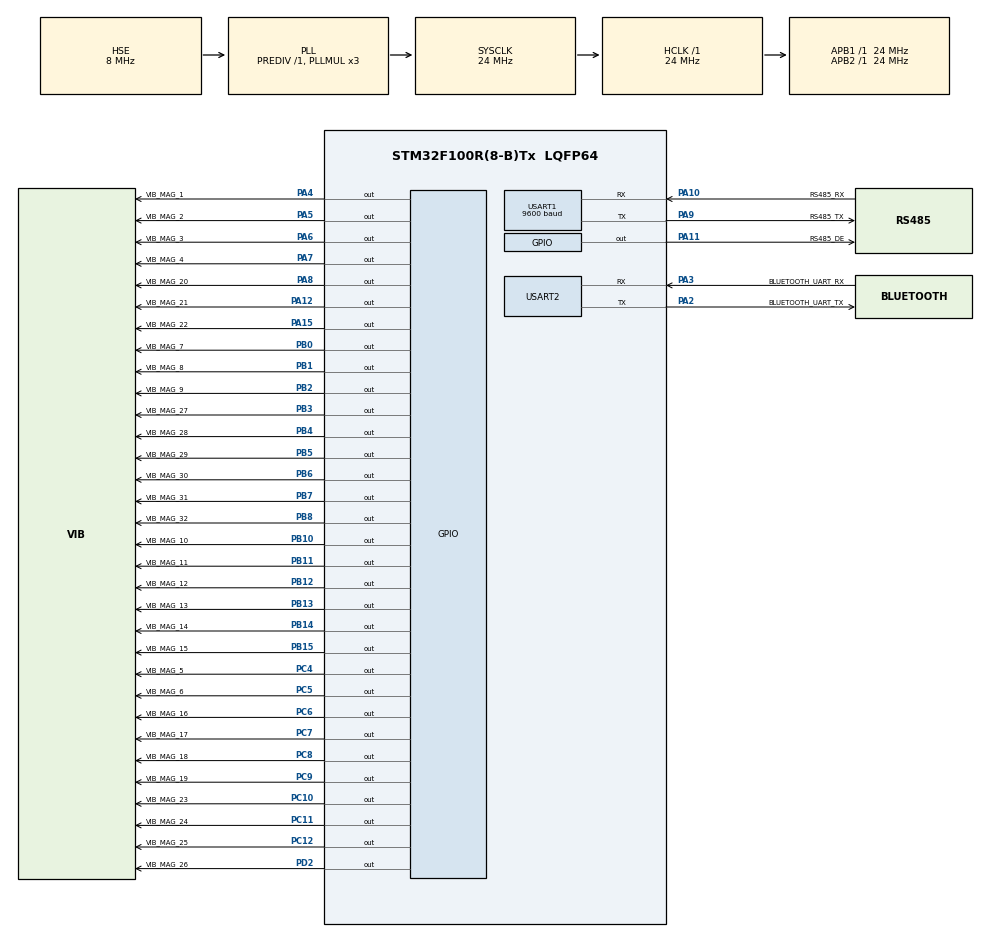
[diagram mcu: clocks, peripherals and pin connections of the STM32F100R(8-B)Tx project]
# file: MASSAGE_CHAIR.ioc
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FREERTOS.Tasks01=defaultTask,-3,128,StartDefaultTask,As weak,NULL,Dynamic,NULL,NULL
Mcu.Family=STM32F1
Mcu.Name=STM32F100R(8-B)Tx
Mcu.Package=LQFP64
NVIC.PriorityGroup=NVIC_PRIORITYGROUP_4
PA10.GPIO_Label=RS485_RX
PA10.Mode=Asynchronous
PA10.Signal=USART1_RX
PA11.GPIO_Label=RS485_DE
PA11.Signal=GPIO_Output
PA12.GPIO_Label=VIB_MAG_21
PA12.Signal=GPIO_Output
PA13.Mode=Serial_Wire
PA13.Signal=SYS_JTMS-SWDIO
PA14.Mode=Serial_Wire
PA14.Signal=SYS_JTCK-SWCLK
PA15.GPIO_Label=VIB_MAG_22
PA15.Signal=GPIO_Output
PA2.GPIO_Label=BLUETOOTH_UART_TX
PA2.Mode=Asynchronous
PA2.Signal=USART2_TX
PA3.GPIO_Label=BLUETOOTH_UART_RX
PA3.Mode=Asynchronous
PA3.Signal=USART2_RX
PA4.GPIO_Label=VIB_MAG_1
PA4.Signal=GPIO_Output
PA5.GPIO_Label=VIB_MAG_2
PA5.Signal=GPIO_Output
PA6.GPIO_Label=VIB_MAG_3
PA6.Signal=GPIO_Output
PA7.GPIO_Label=VIB_MAG_4
PA7.Signal=GPIO_Output
PA8.GPIO_Label=VIB_MAG_20
PA8.Signal=GPIO_Output
PA9.GPIO_Label=RS485_TX
PA9.Mode=Asynchronous
PA9.Signal=USART1_TX
PB0.GPIO_Label=VIB_MAG_7
PB0.Signal=GPIO_Output
PB1.GPIO_Label=VIB_MAG_8
PB1.Signal=GPIO_Output
PB10.GPIO_Label=VIB_MAG_10
PB10.Signal=GPIO_Output
PB11.GPIO_Label=VIB_MAG_11
PB11.Signal=GPIO_Output
PB12.GPIO_Label=VIB_MAG_12
PB12.Signal=GPIO_Output
PB13.GPIO_Label=VIB_MAG_13
PB13.Signal=GPIO_Output
PB14.GPIO_Label=VIB_MAG_14
PB14.Signal=GPIO_Output
PB15.GPIO_Label=VIB_MAG_15
PB15.Signal=GPIO_Output
PB2.GPIO_Label=VIB_MAG_9
PB2.Signal=GPIO_Output
PB3.GPIO_Label=VIB_MAG_27
PB3.Signal=GPIO_Output
PB4.GPIO_Label=VIB_MAG_28
PB4.Signal=GPIO_Output
PB5.GPIO_Label=VIB_MAG_29
PB5.Signal=GPIO_Output
PB6.GPIO_Label=VIB_MAG_30
PB6.Signal=GPIO_Output
PB7.GPIO_Label=VIB_MAG_31
PB7.Signal=GPIO_Output
PB8.GPIO_Label=VIB_MAG_32
PB8.Signal=GPIO_Output
PC10.GPIO_Label=VIB_MAG_23
PC10.Signal=GPIO_Output
PC11.GPIO_Label=VIB_MAG_24
PC11.Signal=GPIO_Output
PC12.GPIO_Label=VIB_MAG_25
PC12.Signal=GPIO_Output
PC4.GPIO_Label=VIB_MAG_5
PC4.Signal=GPIO_Output
PC5.GPIO_Label=VIB_MAG_6
PC5.Signal=GPIO_Output
PC6.GPIO_Label=VIB_MAG_16
PC6.Signal=GPIO_Output
PC7.GPIO_Label=VIB_MAG_17
PC7.Signal=GPIO_Output
PC8.GPIO_Label=VIB_MAG_18
PC8.Signal=GPIO_Output
PC9.GPIO_Label=VIB_MAG_19
PC9.Signal=GPIO_Output
PD0-OSC_IN.Mode=HSE-External-Oscillator
PD0-OSC_IN.Signal=RCC_OSC_IN
PD1-OSC_OUT.Mode=HSE-External-Oscillator
PD1-OSC_OUT.Signal=RCC_OSC_OUT
PD2.GPIO_Label=VIB_MAG_26
PD2.Signal=GPIO_Output
ProjectManager.HeapSize=0x200
ProjectManager.StackSize=0x400
ProjectManager.TargetToolchain=MDK-ARM V5
RCC.AHBFreq_Value=24000000
RCC.APB1Freq_Value=24000000
RCC.APB1TimFreq_Value=24000000
RCC.APB2Freq_Value=24000000
RCC.APB2TimFreq_Value=24000000
RCC.HCLKFreq_Value=24000000
RCC.PLLMUL=RCC_PLL_MUL3
RCC.PLLSource=RCC_PLLSOURCE_HSE
RCC.SYSCLKFreq_VALUE=24000000
RCC.SYSCLKSource=RCC_SYSCLKSOURCE_PLLCLK
USART1.BaudRate=9600
USART1.VirtualMode=VM_ASYNC
USART2.VirtualMode=VM_ASYNC
VP_FREERTOS_VS_ENABLE.Mode=Enabled
board=MASSAGE_CHAIR

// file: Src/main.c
/**
  ******************************************************************************
  * File Name          : main.c
  * Description        : Main program body
  ******************************************************************************
  * This notice applies to any and all portions of this file
  * that are not between comment pairs USER CODE BEGIN and
  * USER CODE END. Other portions of this file, whether
  * inserted by the user or by software development tools
  * are owned by their respective copyright owners.
  *
  * Copyright (c) 2017 STMicroelectronics International N.V.
  * All rights reserved.
  *
  * Redistribution and use in source and binary forms, with or without
  * modification, are permitted, provided that the following conditions are met:
  *
  * 1. Redistribution of source code must retain the above copyright notice,
  *    this list of conditions and the following disclaimer.
  * 2. Redistributions in binary form must reproduce the above copyright notice,
  *    this list of conditions and the following disclaimer in the documentation
  *    and/or other materials provided with the distribution.
  * 3. Neither the name of STMicroelectronics nor the names of other
  *    contributors to this software may be used to endorse or promote products
  *    derived from this software without specific written permission.
  * 4. This software, including modifications and/or derivative works of this
  *    software, must execute solely and exclusively on microcontroller or
  *    microprocessor devices manufactured by or for STMicroelectronics.
  * 5. Redistribution and use of this software other than as permitted under
  *    this license is void and will automatically terminate your rights under
  *    this license.
  *
  * THIS SOFTWARE IS PROVIDED BY STMICROELECTRONICS AND CONTRIBUTORS "AS IS"
  * AND ANY EXPRESS, IMPLIED OR STATUTORY WARRANTIES, INCLUDING, BUT NOT
  * LIMITED TO, THE IMPLIED WARRANTIES OF MERCHANTABILITY, FITNESS FOR A
  * PARTICULAR PURPOSE AND NON-INFRINGEMENT OF THIRD PARTY INTELLECTUAL PROPERTY
  * RIGHTS ARE DISCLAIMED TO THE FULLEST EXTENT PERMITTED BY LAW. IN NO EVENT
  * SHALL STMICROELECTRONICS OR CONTRIBUTORS BE LIABLE FOR ANY DIRECT, INDIRECT,
  * INCIDENTAL, SPECIAL, EXEMPLARY, OR CONSEQUENTIAL DAMAGES (INCLUDING, BUT NOT
  * LIMITED TO, PROCUREMENT OF SUBSTITUTE GOODS OR SERVICES; LOSS OF USE, DATA,
  * OR PROFITS; OR BUSINESS INTERRUPTION) HOWEVER CAUSED AND ON ANY THEORY OF
  * LIABILITY, WHETHER IN CONTRACT, STRICT LIABILITY, OR TORT (INCLUDING
  * NEGLIGENCE OR OTHERWISE) ARISING IN ANY WAY OUT OF THE USE OF THIS SOFTWARE,
  * EVEN IF ADVISED OF THE POSSIBILITY OF SUCH DAMAGE.
  *
  ******************************************************************************
  */
#include "main.h"
#include "stm32f1xx_hal.h"
#include "cmsis_os.h"

/* USER CODE BEGIN Includes */
#include "cmd_iface.h"
/* USER CODE END Includes */

UART_HandleTypeDef huart1;
UART_HandleTypeDef huart2;

osThreadId defaultTaskHandle;

/* USER CODE BEGIN PV */
/* Private variables ---------------------------------------------------------*/

/* USER CODE END PV */

void SystemClock_Config(void);
static void MX_GPIO_Init(void);
static void MX_USART1_UART_Init(void);
static void MX_USART2_UART_Init(void);
void StartDefaultTask(void const * argument);

/* USER CODE BEGIN PFP */
/* Private function prototypes -----------------------------------------------*/

/* USER CODE END PFP */

int main(void)
{

  /* MCU Configuration----------------------------------------------------------*/

  /* Reset of all peripherals, Initializes the Flash interface and the Systick. */
  HAL_Init();

  /* Configure the system clock */
  SystemClock_Config();

  /* Initialize all configured peripherals */
  MX_GPIO_Init();
  MX_USART1_UART_Init();
  MX_USART2_UART_Init();

  /* USER CODE BEGIN 2 */
	Cmd_Iface_Init();
  /* USER CODE END 2 */

  /* Create the thread(s) */
  /* definition and creation of defaultTask */
  osThreadDef(defaultTask, StartDefaultTask, osPriorityIdle, 0, 128);
  defaultTaskHandle = osThreadCreate(osThread(defaultTask), NULL);

  /* Start scheduler */
  osKernelStart();

  /* We should never get here as control is now taken by the scheduler */

  /* Infinite loop */
  while (1)
  {

  }

}

/** System Clock Configuration
*/
void SystemClock_Config(void)
{

  RCC_OscInitTypeDef RCC_OscInitStruct;
  RCC_ClkInitTypeDef RCC_ClkInitStruct;

    /**Initializes the CPU, AHB and APB busses clocks
    */
  RCC_OscInitStruct.OscillatorType = RCC_OSCILLATORTYPE_HSE;
  RCC_OscInitStruct.HSEState = RCC_HSE_ON;
  RCC_OscInitStruct.HSEPredivValue = RCC_HSE_PREDIV_DIV1;
  RCC_OscInitStruct.PLL.PLLState = RCC_PLL_ON;
  RCC_OscInitStruct.PLL.PLLSource = RCC_PLLSOURCE_HSE;
  RCC_OscInitStruct.PLL.PLLMUL = RCC_PLL_MUL3;
  if (HAL_RCC_OscConfig(&RCC_OscInitStruct) != HAL_OK)
  {
    _Error_Handler(__FILE__, __LINE__);
  }

    /**Initializes the CPU, AHB and APB busses clocks
    */
  RCC_ClkInitStruct.ClockType = RCC_CLOCKTYPE_HCLK|RCC_CLOCKTYPE_SYSCLK
                              |RCC_CLOCKTYPE_PCLK1|RCC_CLOCKTYPE_PCLK2;
  RCC_ClkInitStruct.SYSCLKSource = RCC_SYSCLKSOURCE_PLLCLK;
  RCC_ClkInitStruct.AHBCLKDivider = RCC_SYSCLK_DIV1;
  RCC_ClkInitStruct.APB1CLKDivider = RCC_HCLK_DIV1;
  RCC_ClkInitStruct.APB2CLKDivider = RCC_HCLK_DIV1;

  if (HAL_RCC_ClockConfig(&RCC_ClkInitStruct, FLASH_LATENCY_0) != HAL_OK)
  {
    _Error_Handler(__FILE__, __LINE__);
  }

    /**Configure the Systick interrupt time
    */
  HAL_SYSTICK_Config(HAL_RCC_GetHCLKFreq()/1000);

    /**Configure the Systick
    */
  HAL_SYSTICK_CLKSourceConfig(SYSTICK_CLKSOURCE_HCLK);

  /* SysTick_IRQn interrupt configuration */
  HAL_NVIC_SetPriority(SysTick_IRQn, 15, 0);
}

/* USART1 init function */
static void MX_USART1_UART_Init(void)
{

  huart1.Instance = USART1;
  huart1.Init.BaudRate = 9600;
  huart1.Init.WordLength = UART_WORDLENGTH_8B;
  huart1.Init.StopBits = UART_STOPBITS_1;
  huart1.Init.Parity = UART_PARITY_NONE;
  huart1.Init.Mode = UART_MODE_TX_RX;
  huart1.Init.HwFlowCtl = UART_HWCONTROL_NONE;
  huart1.Init.OverSampling = UART_OVERSAMPLING_16;
  if (HAL_UART_Init(&huart1) != HAL_OK)
  {
    _Error_Handler(__FILE__, __LINE__);
  }

}

/* USART2 init function */
static void MX_USART2_UART_Init(void)
{

  huart2.Instance = USART2;
  huart2.Init.BaudRate = 115200;
  huart2.Init.WordLength = UART_WORDLENGTH_8B;
  huart2.Init.StopBits = UART_STOPBITS_1;
  huart2.Init.Parity = UART_PARITY_NONE;
  huart2.Init.Mode = UART_MODE_TX_RX;
  huart2.Init.HwFlowCtl = UART_HWCONTROL_NONE;
  huart2.Init.OverSampling = UART_OVERSAMPLING_16;
  if (HAL_UART_Init(&huart2) != HAL_OK)
  {
    _Error_Handler(__FILE__, __LINE__);
  }

}

/** Configure pins as
        * Analog
        * Input
        * Output
        * EVENT_OUT
        * EXTI
*/
static void MX_GPIO_Init(void)
{

  GPIO_InitTypeDef GPIO_InitStruct;

  /* GPIO Ports Clock Enable */
  __HAL_RCC_GPIOD_CLK_ENABLE();
  __HAL_RCC_GPIOA_CLK_ENABLE();
  __HAL_RCC_GPIOC_CLK_ENABLE();
  __HAL_RCC_GPIOB_CLK_ENABLE();

  /*Configure GPIO pin Output Level */
  HAL_GPIO_WritePin(GPIOA, VIB_MAG_1_Pin|VIB_MAG_2_Pin|VIB_MAG_3_Pin|VIB_MAG_4_Pin
                          |VIB_MAG_20_Pin|RS485_DE_Pin|VIB_MAG_21_Pin|VIB_MAG_22_Pin, GPIO_PIN_RESET);

  /*Configure GPIO pin Output Level */
  HAL_GPIO_WritePin(GPIOC, VIB_MAG_5_Pin|VIB_MAG_6_Pin|VIB_MAG_16_Pin|VIB_MAG_17_Pin
                          |VIB_MAG_18_Pin|VIB_MAG_19_Pin|VIB_MAG_23_Pin|VIB_MAG_24_Pin
                          |VIB_MAG_25_Pin, GPIO_PIN_RESET);

  /*Configure GPIO pin Output Level */
  HAL_GPIO_WritePin(GPIOB, VIB_MAG_7_Pin|VIB_MAG_8_Pin|VIB_MAG_9_Pin|VIB_MAG_10_Pin
                          |VIB_MAG_11_Pin|VIB_MAG_12_Pin|VIB_MAG_13_Pin|VIB_MAG_14_Pin
                          |VIB_MAG_15_Pin|VIB_MAG_27_Pin|VIB_MAG_28_Pin|VIB_MAG_29_Pin
                          |VIB_MAG_30_Pin|VIB_MAG_31_Pin|VIB_MAG_32_Pin, GPIO_PIN_RESET);

  /*Configure GPIO pin Output Level */
  HAL_GPIO_WritePin(VIB_MAG_26_GPIO_Port, VIB_MAG_26_Pin, GPIO_PIN_RESET);

  /*Configure GPIO pins : VIB_MAG_1_Pin VIB_MAG_2_Pin VIB_MAG_3_Pin VIB_MAG_4_Pin
                           VIB_MAG_20_Pin RS485_DE_Pin VIB_MAG_21_Pin VIB_MAG_22_Pin */
  GPIO_InitStruct.Pin = VIB_MAG_1_Pin|VIB_MAG_2_Pin|VIB_MAG_3_Pin|VIB_MAG_4_Pin
                          |VIB_MAG_20_Pin|RS485_DE_Pin|VIB_MAG_21_Pin|VIB_MAG_22_Pin;
  GPIO_InitStruct.Mode = GPIO_MODE_OUTPUT_PP;
  GPIO_InitStruct.Speed = GPIO_SPEED_FREQ_LOW;
  HAL_GPIO_Init(GPIOA, &GPIO_InitStruct);

  /*Configure GPIO pins : VIB_MAG_5_Pin VIB_MAG_6_Pin VIB_MAG_16_Pin VIB_MAG_17_Pin
                           VIB_MAG_18_Pin VIB_MAG_19_Pin VIB_MAG_23_Pin VIB_MAG_24_Pin
                           VIB_MAG_25_Pin */
  GPIO_InitStruct.Pin = VIB_MAG_5_Pin|VIB_MAG_6_Pin|VIB_MAG_16_Pin|VIB_MAG_17_Pin
                          |VIB_MAG_18_Pin|VIB_MAG_19_Pin|VIB_MAG_23_Pin|VIB_MAG_24_Pin
                          |VIB_MAG_25_Pin;
  GPIO_InitStruct.Mode = GPIO_MODE_OUTPUT_PP;
  GPIO_InitStruct.Speed = GPIO_SPEED_FREQ_LOW;
  HAL_GPIO_Init(GPIOC, &GPIO_InitStruct);

  /*Configure GPIO pins : VIB_MAG_7_Pin VIB_MAG_8_Pin VIB_MAG_9_Pin VIB_MAG_10_Pin
                           VIB_MAG_11_Pin VIB_MAG_12_Pin VIB_MAG_13_Pin VIB_MAG_14_Pin
                           VIB_MAG_15_Pin VIB_MAG_27_Pin VIB_MAG_28_Pin VIB_MAG_29_Pin
                           VIB_MAG_30_Pin VIB_MAG_31_Pin VIB_MAG_32_Pin */
  GPIO_InitStruct.Pin = VIB_MAG_7_Pin|VIB_MAG_8_Pin|VIB_MAG_9_Pin|VIB_MAG_10_Pin
                          |VIB_MAG_11_Pin|VIB_MAG_12_Pin|VIB_MAG_13_Pin|VIB_MAG_14_Pin
                          |VIB_MAG_15_Pin|VIB_MAG_27_Pin|VIB_MAG_28_Pin|VIB_MAG_29_Pin
                          |VIB_MAG_30_Pin|VIB_MAG_31_Pin|VIB_MAG_32_Pin;
  GPIO_InitStruct.Mode = GPIO_MODE_OUTPUT_PP;
  GPIO_InitStruct.Speed = GPIO_SPEED_FREQ_LOW;
  HAL_GPIO_Init(GPIOB, &GPIO_InitStruct);

  /*Configure GPIO pin : VIB_MAG_26_Pin */
  GPIO_InitStruct.Pin = VIB_MAG_26_Pin;
  GPIO_InitStruct.Mode = GPIO_MODE_OUTPUT_PP;
  GPIO_InitStruct.Speed = GPIO_SPEED_FREQ_LOW;
  HAL_GPIO_Init(VIB_MAG_26_GPIO_Port, &GPIO_InitStruct);

}

/* StartDefaultTask function */
__weak void StartDefaultTask(void const * argument)
{

  for(;;)
  {
    osDelay(1);
  }
}

void _Error_Handler(char * file, int line)
{
  while(1)
  {
  }
}

/************************ (C) COPYRIGHT STMicroelectronics *****END OF FILE****/
